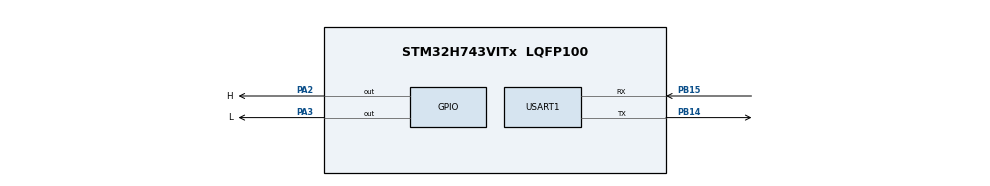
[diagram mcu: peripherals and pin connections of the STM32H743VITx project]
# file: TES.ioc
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CORTEX_M7.default_mode_Activation=1
Mcu.Family=STM32H7
Mcu.Name=STM32H743VITx
Mcu.Package=LQFP100
NVIC.PriorityGroup=NVIC_PRIORITYGROUP_4
NVIC.USART1_IRQn=true\:0\:0\:false\:false\:true\:true\:true\:true
PA2.GPIO_Label=H
PA2.GPIO_ModeDefaultOutputPP=GPIO_MODE_OUTPUT_PP
PA2.GPIO_PuPd=GPIO_NOPULL
PA2.PinState=GPIO_PIN_SET
PA2.Signal=GPIO_Output
PA3.GPIO_Label=L
PA3.Signal=GPIO_Output
PB14.Mode=Asynchronous
PB14.Signal=USART1_TX
PB15.Mode=Asynchronous
PB15.Signal=USART1_RX
PC14-OSC32_IN\ (OSC32_IN).Mode=LSE-External-Oscillator
PC14-OSC32_IN\ (OSC32_IN).Signal=RCC_OSC32_IN
PC15-OSC32_OUT\ (OSC32_OUT).Mode=LSE-External-Oscillator
PC15-OSC32_OUT\ (OSC32_OUT).Signal=RCC_OSC32_OUT
PH0-OSC_IN\ (PH0).Mode=HSE-External-Oscillator
PH0-OSC_IN\ (PH0).Signal=RCC_OSC_IN
PH1-OSC_OUT\ (PH1).Mode=HSE-External-Oscillator
PH1-OSC_OUT\ (PH1).Signal=RCC_OSC_OUT
ProjectManager.HeapSize=0x200
ProjectManager.StackSize=0x400
ProjectManager.TargetToolchain=MDK-ARM V5.32
RCC.ADCFreq_Value=129000000
RCC.APB1Freq_Value=64000000
RCC.APB2Freq_Value=32000000
RCC.APB3Freq_Value=64000000
RCC.APB4Freq_Value=64000000
RCC.CortexFreq_Value=64000000
RCC.D2PPRE2=RCC_APB2_DIV2
RCC.HCLKFreq_Value=64000000
RCC.SYSCLKFreq_VALUE=64000000
RCC.USBFreq_Value=129000000
USART1.VirtualMode-Asynchronous=VM_ASYNC
VP_MEMORYMAP_VS_MEMORYMAP.Mode=CurAppReg
board=custom

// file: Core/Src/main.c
#include "main.h"
#include "memorymap.h"
#include "usart.h"
#include "gpio.h"
#include <stdio.h>
//
#include "MyUsart.h"
//

//
void SystemClock_Config(void);
static void MPU_Config(void);
//

#define KEY0 (HAL_GPIO_ReadPin(GPIOA, GPIO_PIN_0))

uint8_t TD[5] = {0x11, 0x22, 0x33, 0x44, 0x55};

int main(void){
	MPU_Config();
	HAL_Init();
	MX_GPIO_Init();
	MX_USART1_UART_Init();
	HAL_UART_Receive_IT(&huart1, &rx_buff[cnt_rx ++], 1);
	Serial_TJC_SendTxt(1, "It's My Go!!!!!");
  Serial_TJC_SendTxt(1, "It's My Go!!!!!");
	printf_s("[Init]");

	while (1){
		//if (KEY0 == 1) Serial_TJC_SendTxt(5, "KEY_ON");
		//else Serial_TJC_SendTxt(5, "KEY_OFF");
		MyUart_task();
		//Serial_TJC_SendTxt(0, "It'");
		HAL_Delay(10);
	}
}

void SystemClock_Config(void)
{
  RCC_OscInitTypeDef RCC_OscInitStruct = {0};
  RCC_ClkInitTypeDef RCC_ClkInitStruct = {0};

  /** Supply configuration update enable
  */
  HAL_PWREx_ConfigSupply(PWR_LDO_SUPPLY);

  /** Configure the main internal regulator output voltage
  */
  __HAL_PWR_VOLTAGESCALING_CONFIG(PWR_REGULATOR_VOLTAGE_SCALE3);

  while(!__HAL_PWR_GET_FLAG(PWR_FLAG_VOSRDY)) {}

  /** Initializes the RCC Oscillators according to the specified parameters
  * in the RCC_OscInitTypeDef structure.
  */
  RCC_OscInitStruct.OscillatorType = RCC_OSCILLATORTYPE_HSI;
  RCC_OscInitStruct.HSIState = RCC_HSI_DIV1;
  RCC_OscInitStruct.HSICalibrationValue = RCC_HSICALIBRATION_DEFAULT;
  RCC_OscInitStruct.PLL.PLLState = RCC_PLL_NONE;
  if (HAL_RCC_OscConfig(&RCC_OscInitStruct) != HAL_OK)
  {
    Error_Handler();
  }

  /** Initializes the CPU, AHB and APB buses clocks
  */
  RCC_ClkInitStruct.ClockType = RCC_CLOCKTYPE_HCLK|RCC_CLOCKTYPE_SYSCLK
                              |RCC_CLOCKTYPE_PCLK1|RCC_CLOCKTYPE_PCLK2
                              |RCC_CLOCKTYPE_D3PCLK1|RCC_CLOCKTYPE_D1PCLK1;
  RCC_ClkInitStruct.SYSCLKSource = RCC_SYSCLKSOURCE_HSI;
  RCC_ClkInitStruct.SYSCLKDivider = RCC_SYSCLK_DIV1;
  RCC_ClkInitStruct.AHBCLKDivider = RCC_HCLK_DIV1;
  RCC_ClkInitStruct.APB3CLKDivider = RCC_APB3_DIV1;
  RCC_ClkInitStruct.APB1CLKDivider = RCC_APB1_DIV1;
  RCC_ClkInitStruct.APB2CLKDivider = RCC_APB2_DIV2;
  RCC_ClkInitStruct.APB4CLKDivider = RCC_APB4_DIV1;

  if (HAL_RCC_ClockConfig(&RCC_ClkInitStruct, FLASH_LATENCY_1) != HAL_OK)
  {
    Error_Handler();
  }
}

/* USER CODE BEGIN 4 */
// 重定向函数

/* USER CODE END 4 */

 /* MPU Configuration */

void MPU_Config(void)
{
  MPU_Region_InitTypeDef MPU_InitStruct = {0};

  /* Disables the MPU */
  HAL_MPU_Disable();

  /** Initializes and configures the Region and the memory to be protected
  */
  MPU_InitStruct.Enable = MPU_REGION_ENABLE;
  MPU_InitStruct.Number = MPU_REGION_NUMBER0;
  MPU_InitStruct.BaseAddress = 0x0;
  MPU_InitStruct.Size = MPU_REGION_SIZE_4GB;
  MPU_InitStruct.SubRegionDisable = 0x87;
  MPU_InitStruct.TypeExtField = MPU_TEX_LEVEL0;
  MPU_InitStruct.AccessPermission = MPU_REGION_NO_ACCESS;
  MPU_InitStruct.DisableExec = MPU_INSTRUCTION_ACCESS_DISABLE;
  MPU_InitStruct.IsShareable = MPU_ACCESS_SHAREABLE;
  MPU_InitStruct.IsCacheable = MPU_ACCESS_NOT_CACHEABLE;
  MPU_InitStruct.IsBufferable = MPU_ACCESS_NOT_BUFFERABLE;

  HAL_MPU_ConfigRegion(&MPU_InitStruct);
  /* Enables the MPU */
  HAL_MPU_Enable(MPU_PRIVILEGED_DEFAULT);

}

void Error_Handler(void)
{
  __disable_irq();
  while (1)
  {
  }
}
